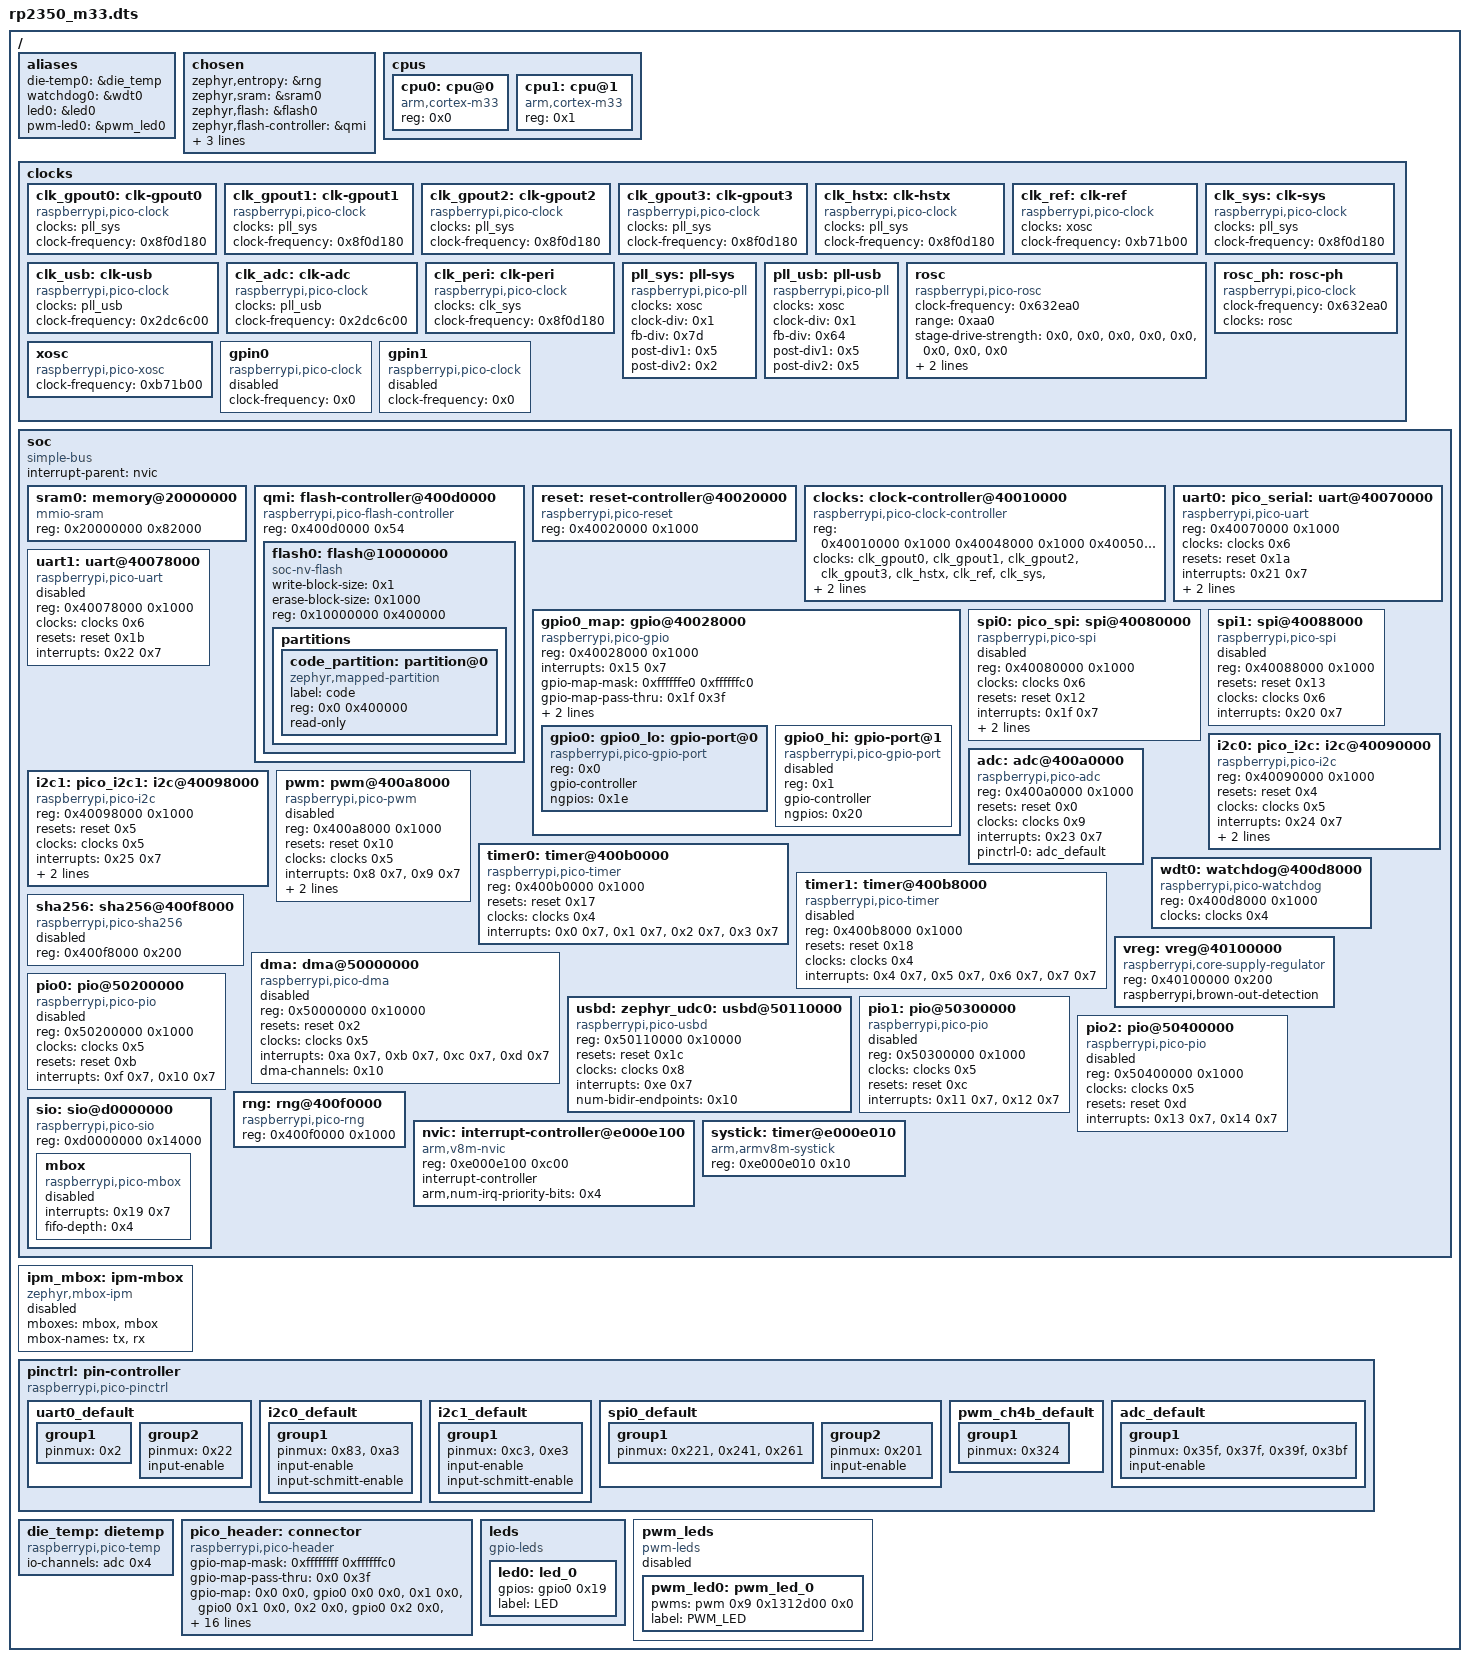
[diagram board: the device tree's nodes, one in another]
/dts-v1/;

/* node '/' defined in zephyr/dts/vendor/raspberrypi/rpi_pico/rp2350.dtsi:19 */
/ {
	#address-cells = < 0x1 >; /* in zephyr/dts/common/skeleton.dtsi:10 */
	#size-cells = < 0x1 >;    /* in zephyr/dts/common/skeleton.dtsi:11 */

	/* node '/aliases' defined in zephyr/dts/vendor/raspberrypi/rpi_pico/rp2350.dtsi:20 */
	aliases {
		die-temp0 = &die_temp; /* in zephyr/dts/vendor/raspberrypi/rpi_pico/rp2350.dtsi:21 */
		watchdog0 = &wdt0;     /* in zephyr/boards/raspberrypi/rpi_pico2/rpi_pico2_cpu0_common.dtsi:26 */
		led0 = &led0;          /* in zephyr/boards/raspberrypi/common/rpi_pico-led.dtsi:29 */
		pwm-led0 = &pwm_led0;  /* in zephyr/boards/raspberrypi/common/rpi_pico-led.dtsi:30 */
	};

	/* node '/chosen' defined in zephyr/dts/vendor/raspberrypi/rpi_pico/rp2350.dtsi:24 */
	chosen {
		zephyr,entropy = &rng;                   /* in zephyr/dts/vendor/raspberrypi/rpi_pico/rp2350.dtsi:25 */
		zephyr,sram = &sram0;                    /* in zephyr/boards/raspberrypi/rpi_pico2/rpi_pico2_cpu0_common.dtsi:17 */
		zephyr,flash = &flash0;                  /* in zephyr/boards/raspberrypi/rpi_pico2/rpi_pico2_cpu0_common.dtsi:18 */
		zephyr,flash-controller = &qmi;          /* in zephyr/boards/raspberrypi/rpi_pico2/rpi_pico2_cpu0_common.dtsi:19 */
		zephyr,console = &uart0;                 /* in zephyr/boards/raspberrypi/rpi_pico2/rpi_pico2_cpu0_common.dtsi:20 */
		zephyr,shell-uart = &uart0;              /* in zephyr/boards/raspberrypi/rpi_pico2/rpi_pico2_cpu0_common.dtsi:21 */
		zephyr,code-partition = &code_partition; /* in zephyr/boards/raspberrypi/rpi_pico2/rpi_pico2_cpu0_common.dtsi:22 */
	};

	/* node '/cpus' defined in zephyr/dts/vendor/raspberrypi/rpi_pico/rp2350.dtsi:28 */
	cpus {
		#address-cells = < 0x1 >; /* in zephyr/dts/vendor/raspberrypi/rpi_pico/rp2350.dtsi:29 */
		#size-cells = < 0x0 >;    /* in zephyr/dts/vendor/raspberrypi/rpi_pico/rp2350.dtsi:30 */

		/* node '/cpus/cpu@0' defined in zephyr/dts/vendor/raspberrypi/rpi_pico/rp2350.dtsi:37 */
		cpu0: cpu@0 {
			reg = < 0x0 >;                 /* in zephyr/dts/vendor/raspberrypi/rpi_pico/rp2350.dtsi:38 */
			compatible = "arm,cortex-m33"; /* in zephyr/dts/arm/raspberrypi/rpi_pico/m33.dtsi:13 */
		};

		/* node '/cpus/cpu@1' defined in zephyr/dts/vendor/raspberrypi/rpi_pico/rp2350.dtsi:41 */
		cpu1: cpu@1 {
			reg = < 0x1 >;                 /* in zephyr/dts/vendor/raspberrypi/rpi_pico/rp2350.dtsi:42 */
			compatible = "arm,cortex-m33"; /* in zephyr/dts/arm/raspberrypi/rpi_pico/m33.dtsi:17 */
		};
	};

	/* node '/clocks' defined in zephyr/dts/vendor/raspberrypi/rpi_pico/rp2350.dtsi:46 */
	clocks {

		/* node '/clocks/clk-gpout0' defined in zephyr/dts/vendor/raspberrypi/rpi_pico/rp2350.dtsi:47 */
		clk_gpout0: clk-gpout0 {
			compatible = "raspberrypi,pico-clock"; /* in zephyr/dts/vendor/raspberrypi/rpi_pico/rp2350.dtsi:48 */
			clocks = < &pll_sys >;                 /* in zephyr/dts/vendor/raspberrypi/rpi_pico/rp2350.dtsi:49 */
			clock-names = "pll_sys";               /* in zephyr/dts/vendor/raspberrypi/rpi_pico/rp2350.dtsi:50 */
			clock-frequency = < 0x8f0d180 >;       /* in zephyr/dts/vendor/raspberrypi/rpi_pico/rp2350.dtsi:51 */
			#clock-cells = < 0x0 >;                /* in zephyr/dts/vendor/raspberrypi/rpi_pico/rp2350.dtsi:52 */
			#address-cells = < 0x0 >;              /* in zephyr/dts/vendor/raspberrypi/rpi_pico/rp2350.dtsi:53 */
			phandle = < 0x7 >;                     /* in zephyr/dts/vendor/raspberrypi/rpi_pico/rp2350.dtsi:230 */
		};

		/* node '/clocks/clk-gpout1' defined in zephyr/dts/vendor/raspberrypi/rpi_pico/rp2350.dtsi:56 */
		clk_gpout1: clk-gpout1 {
			compatible = "raspberrypi,pico-clock"; /* in zephyr/dts/vendor/raspberrypi/rpi_pico/rp2350.dtsi:57 */
			clocks = < &pll_sys >;                 /* in zephyr/dts/vendor/raspberrypi/rpi_pico/rp2350.dtsi:58 */
			clock-names = "pll_sys";               /* in zephyr/dts/vendor/raspberrypi/rpi_pico/rp2350.dtsi:59 */
			clock-frequency = < 0x8f0d180 >;       /* in zephyr/dts/vendor/raspberrypi/rpi_pico/rp2350.dtsi:60 */
			#clock-cells = < 0x0 >;                /* in zephyr/dts/vendor/raspberrypi/rpi_pico/rp2350.dtsi:61 */
			phandle = < 0x8 >;                     /* in zephyr/dts/vendor/raspberrypi/rpi_pico/rp2350.dtsi:230 */
		};

		/* node '/clocks/clk-gpout2' defined in zephyr/dts/vendor/raspberrypi/rpi_pico/rp2350.dtsi:64 */
		clk_gpout2: clk-gpout2 {
			compatible = "raspberrypi,pico-clock"; /* in zephyr/dts/vendor/raspberrypi/rpi_pico/rp2350.dtsi:65 */
			clocks = < &pll_sys >;                 /* in zephyr/dts/vendor/raspberrypi/rpi_pico/rp2350.dtsi:66 */
			clock-names = "pll_sys";               /* in zephyr/dts/vendor/raspberrypi/rpi_pico/rp2350.dtsi:67 */
			clock-frequency = < 0x8f0d180 >;       /* in zephyr/dts/vendor/raspberrypi/rpi_pico/rp2350.dtsi:68 */
			#clock-cells = < 0x0 >;                /* in zephyr/dts/vendor/raspberrypi/rpi_pico/rp2350.dtsi:69 */
			phandle = < 0x9 >;                     /* in zephyr/dts/vendor/raspberrypi/rpi_pico/rp2350.dtsi:230 */
		};

		/* node '/clocks/clk-gpout3' defined in zephyr/dts/vendor/raspberrypi/rpi_pico/rp2350.dtsi:72 */
		clk_gpout3: clk-gpout3 {
			compatible = "raspberrypi,pico-clock"; /* in zephyr/dts/vendor/raspberrypi/rpi_pico/rp2350.dtsi:73 */
			clocks = < &pll_sys >;                 /* in zephyr/dts/vendor/raspberrypi/rpi_pico/rp2350.dtsi:74 */
			clock-names = "pll_sys";               /* in zephyr/dts/vendor/raspberrypi/rpi_pico/rp2350.dtsi:75 */
			clock-frequency = < 0x8f0d180 >;       /* in zephyr/dts/vendor/raspberrypi/rpi_pico/rp2350.dtsi:76 */
			#clock-cells = < 0x0 >;                /* in zephyr/dts/vendor/raspberrypi/rpi_pico/rp2350.dtsi:77 */
			phandle = < 0xa >;                     /* in zephyr/dts/vendor/raspberrypi/rpi_pico/rp2350.dtsi:230 */
		};

		/* node '/clocks/clk-hstx' defined in zephyr/dts/vendor/raspberrypi/rpi_pico/rp2350.dtsi:80 */
		clk_hstx: clk-hstx {
			compatible = "raspberrypi,pico-clock"; /* in zephyr/dts/vendor/raspberrypi/rpi_pico/rp2350.dtsi:81 */
			clocks = < &pll_sys >;                 /* in zephyr/dts/vendor/raspberrypi/rpi_pico/rp2350.dtsi:82 */
			clock-names = "pll_sys";               /* in zephyr/dts/vendor/raspberrypi/rpi_pico/rp2350.dtsi:83 */
			clock-frequency = < 0x8f0d180 >;       /* in zephyr/dts/vendor/raspberrypi/rpi_pico/rp2350.dtsi:84 */
			#clock-cells = < 0x0 >;                /* in zephyr/dts/vendor/raspberrypi/rpi_pico/rp2350.dtsi:85 */
			phandle = < 0xb >;                     /* in zephyr/dts/vendor/raspberrypi/rpi_pico/rp2350.dtsi:230 */
		};

		/* node '/clocks/clk-ref' defined in zephyr/dts/vendor/raspberrypi/rpi_pico/rp2350.dtsi:88 */
		clk_ref: clk-ref {
			compatible = "raspberrypi,pico-clock"; /* in zephyr/dts/vendor/raspberrypi/rpi_pico/rp2350.dtsi:89 */
			clocks = < &xosc >;                    /* in zephyr/dts/vendor/raspberrypi/rpi_pico/rp2350.dtsi:90 */
			clock-names = "xosc";                  /* in zephyr/dts/vendor/raspberrypi/rpi_pico/rp2350.dtsi:91 */
			clock-frequency = < 0xb71b00 >;        /* in zephyr/dts/vendor/raspberrypi/rpi_pico/rp2350.dtsi:92 */
			#clock-cells = < 0x0 >;                /* in zephyr/dts/vendor/raspberrypi/rpi_pico/rp2350.dtsi:93 */
			phandle = < 0xc >;                     /* in zephyr/dts/vendor/raspberrypi/rpi_pico/rp2350.dtsi:230 */
		};

		/* node '/clocks/clk-sys' defined in zephyr/dts/vendor/raspberrypi/rpi_pico/rp2350.dtsi:96 */
		clk_sys: clk-sys {
			compatible = "raspberrypi,pico-clock"; /* in zephyr/dts/vendor/raspberrypi/rpi_pico/rp2350.dtsi:97 */
			clocks = < &pll_sys >;                 /* in zephyr/dts/vendor/raspberrypi/rpi_pico/rp2350.dtsi:98 */
			clock-names = "pll_sys";               /* in zephyr/dts/vendor/raspberrypi/rpi_pico/rp2350.dtsi:99 */
			clock-frequency = < 0x8f0d180 >;       /* in zephyr/dts/vendor/raspberrypi/rpi_pico/rp2350.dtsi:100 */
			#clock-cells = < 0x0 >;                /* in zephyr/dts/vendor/raspberrypi/rpi_pico/rp2350.dtsi:101 */
			phandle = < 0x4 >;                     /* in zephyr/dts/vendor/raspberrypi/rpi_pico/rp2350.dtsi:122 */
		};

		/* node '/clocks/clk-usb' defined in zephyr/dts/vendor/raspberrypi/rpi_pico/rp2350.dtsi:104 */
		clk_usb: clk-usb {
			compatible = "raspberrypi,pico-clock"; /* in zephyr/dts/vendor/raspberrypi/rpi_pico/rp2350.dtsi:105 */
			clocks = < &pll_usb >;                 /* in zephyr/dts/vendor/raspberrypi/rpi_pico/rp2350.dtsi:106 */
			clock-names = "pll_usb";               /* in zephyr/dts/vendor/raspberrypi/rpi_pico/rp2350.dtsi:107 */
			clock-frequency = < 0x2dc6c00 >;       /* in zephyr/dts/vendor/raspberrypi/rpi_pico/rp2350.dtsi:108 */
			#clock-cells = < 0x0 >;                /* in zephyr/dts/vendor/raspberrypi/rpi_pico/rp2350.dtsi:109 */
			phandle = < 0xe >;                     /* in zephyr/dts/vendor/raspberrypi/rpi_pico/rp2350.dtsi:230 */
		};

		/* node '/clocks/clk-adc' defined in zephyr/dts/vendor/raspberrypi/rpi_pico/rp2350.dtsi:112 */
		clk_adc: clk-adc {
			compatible = "raspberrypi,pico-clock"; /* in zephyr/dts/vendor/raspberrypi/rpi_pico/rp2350.dtsi:113 */
			clocks = < &pll_usb >;                 /* in zephyr/dts/vendor/raspberrypi/rpi_pico/rp2350.dtsi:114 */
			clock-names = "pll_usb";               /* in zephyr/dts/vendor/raspberrypi/rpi_pico/rp2350.dtsi:115 */
			clock-frequency = < 0x2dc6c00 >;       /* in zephyr/dts/vendor/raspberrypi/rpi_pico/rp2350.dtsi:116 */
			#clock-cells = < 0x0 >;                /* in zephyr/dts/vendor/raspberrypi/rpi_pico/rp2350.dtsi:117 */
			phandle = < 0xf >;                     /* in zephyr/dts/vendor/raspberrypi/rpi_pico/rp2350.dtsi:230 */
		};

		/* node '/clocks/clk-peri' defined in zephyr/dts/vendor/raspberrypi/rpi_pico/rp2350.dtsi:120 */
		clk_peri: clk-peri {
			compatible = "raspberrypi,pico-clock"; /* in zephyr/dts/vendor/raspberrypi/rpi_pico/rp2350.dtsi:121 */
			clocks = < &clk_sys >;                 /* in zephyr/dts/vendor/raspberrypi/rpi_pico/rp2350.dtsi:122 */
			clock-names = "clk_sys";               /* in zephyr/dts/vendor/raspberrypi/rpi_pico/rp2350.dtsi:123 */
			clock-frequency = < 0x8f0d180 >;       /* in zephyr/dts/vendor/raspberrypi/rpi_pico/rp2350.dtsi:124 */
			#clock-cells = < 0x0 >;                /* in zephyr/dts/vendor/raspberrypi/rpi_pico/rp2350.dtsi:125 */
			phandle = < 0xd >;                     /* in zephyr/dts/vendor/raspberrypi/rpi_pico/rp2350.dtsi:230 */
		};

		/* node '/clocks/pll-sys' defined in zephyr/dts/vendor/raspberrypi/rpi_pico/rp2350.dtsi:128 */
		pll_sys: pll-sys {
			compatible = "raspberrypi,pico-pll"; /* in zephyr/dts/vendor/raspberrypi/rpi_pico/rp2350.dtsi:129 */
			clocks = < &xosc >;                  /* in zephyr/dts/vendor/raspberrypi/rpi_pico/rp2350.dtsi:130 */
			clock-names = "xosc";                /* in zephyr/dts/vendor/raspberrypi/rpi_pico/rp2350.dtsi:131 */
			clock-div = < 0x1 >;                 /* in zephyr/dts/vendor/raspberrypi/rpi_pico/rp2350.dtsi:132 */
			fb-div = < 0x7d >;                   /* in zephyr/dts/vendor/raspberrypi/rpi_pico/rp2350.dtsi:133 */
			post-div1 = < 0x5 >;                 /* in zephyr/dts/vendor/raspberrypi/rpi_pico/rp2350.dtsi:134 */
			post-div2 = < 0x2 >;                 /* in zephyr/dts/vendor/raspberrypi/rpi_pico/rp2350.dtsi:135 */
			#clock-cells = < 0x0 >;              /* in zephyr/dts/vendor/raspberrypi/rpi_pico/rp2350.dtsi:136 */
			phandle = < 0x1 >;                   /* in zephyr/dts/vendor/raspberrypi/rpi_pico/rp2350.dtsi:49 */
		};

		/* node '/clocks/pll-usb' defined in zephyr/dts/vendor/raspberrypi/rpi_pico/rp2350.dtsi:139 */
		pll_usb: pll-usb {
			compatible = "raspberrypi,pico-pll"; /* in zephyr/dts/vendor/raspberrypi/rpi_pico/rp2350.dtsi:140 */
			clocks = < &xosc >;                  /* in zephyr/dts/vendor/raspberrypi/rpi_pico/rp2350.dtsi:141 */
			clock-names = "xosc";                /* in zephyr/dts/vendor/raspberrypi/rpi_pico/rp2350.dtsi:142 */
			clock-div = < 0x1 >;                 /* in zephyr/dts/vendor/raspberrypi/rpi_pico/rp2350.dtsi:143 */
			fb-div = < 0x64 >;                   /* in zephyr/dts/vendor/raspberrypi/rpi_pico/rp2350.dtsi:144 */
			post-div1 = < 0x5 >;                 /* in zephyr/dts/vendor/raspberrypi/rpi_pico/rp2350.dtsi:145 */
			post-div2 = < 0x5 >;                 /* in zephyr/dts/vendor/raspberrypi/rpi_pico/rp2350.dtsi:146 */
			#clock-cells = < 0x0 >;              /* in zephyr/dts/vendor/raspberrypi/rpi_pico/rp2350.dtsi:147 */
			phandle = < 0x3 >;                   /* in zephyr/dts/vendor/raspberrypi/rpi_pico/rp2350.dtsi:106 */
		};

		/* node '/clocks/rosc' defined in zephyr/dts/vendor/raspberrypi/rpi_pico/rp2350.dtsi:150 */
		rosc: rosc {
			compatible = "raspberrypi,pico-rosc"; /* in zephyr/dts/vendor/raspberrypi/rpi_pico/rp2350.dtsi:151 */
			clock-frequency = < 0x632ea0 >;       /* in zephyr/dts/vendor/raspberrypi/rpi_pico/rp2350.dtsi:152 */
			range = < 0xaa0 >;                    /* in zephyr/dts/vendor/raspberrypi/rpi_pico/rp2350.dtsi:153 */
			stage-drive-strength = < 0x0 >,
			                       < 0x0 >,
			                       < 0x0 >,
			                       < 0x0 >,
			                       < 0x0 >,
			                       < 0x0 >,
			                       < 0x0 >,
			                       < 0x0 >;       /* in zephyr/dts/vendor/raspberrypi/rpi_pico/rp2350.dtsi:154 */
			clock-div = < 0x10 >;                 /* in zephyr/dts/vendor/raspberrypi/rpi_pico/rp2350.dtsi:155 */
			phase = < 0x0 >;                      /* in zephyr/dts/vendor/raspberrypi/rpi_pico/rp2350.dtsi:156 */
			#clock-cells = < 0x0 >;               /* in zephyr/dts/vendor/raspberrypi/rpi_pico/rp2350.dtsi:157 */
			phandle = < 0x5 >;                    /* in zephyr/dts/vendor/raspberrypi/rpi_pico/rp2350.dtsi:163 */
		};

		/* node '/clocks/rosc-ph' defined in zephyr/dts/vendor/raspberrypi/rpi_pico/rp2350.dtsi:160 */
		rosc_ph: rosc-ph {
			compatible = "raspberrypi,pico-clock"; /* in zephyr/dts/vendor/raspberrypi/rpi_pico/rp2350.dtsi:161 */
			clock-frequency = < 0x632ea0 >;        /* in zephyr/dts/vendor/raspberrypi/rpi_pico/rp2350.dtsi:162 */
			clocks = < &rosc >;                    /* in zephyr/dts/vendor/raspberrypi/rpi_pico/rp2350.dtsi:163 */
			clock-names = "rosc";                  /* in zephyr/dts/vendor/raspberrypi/rpi_pico/rp2350.dtsi:164 */
			#clock-cells = < 0x0 >;                /* in zephyr/dts/vendor/raspberrypi/rpi_pico/rp2350.dtsi:165 */
			phandle = < 0x10 >;                    /* in zephyr/dts/vendor/raspberrypi/rpi_pico/rp2350.dtsi:230 */
		};

		/* node '/clocks/xosc' defined in zephyr/dts/vendor/raspberrypi/rpi_pico/rp2350.dtsi:168 */
		xosc: xosc {
			compatible = "raspberrypi,pico-xosc"; /* in zephyr/dts/vendor/raspberrypi/rpi_pico/rp2350.dtsi:169 */
			clock-frequency = < 0xb71b00 >;       /* in zephyr/dts/vendor/raspberrypi/rpi_pico/rp2350.dtsi:170 */
			#clock-cells = < 0x0 >;               /* in zephyr/dts/vendor/raspberrypi/rpi_pico/rp2350.dtsi:171 */
			phandle = < 0x2 >;                    /* in zephyr/dts/vendor/raspberrypi/rpi_pico/rp2350.dtsi:90 */
		};

		/* node '/clocks/gpin0' defined in zephyr/dts/vendor/raspberrypi/rpi_pico/rp2350.dtsi:174 */
		gpin0: gpin0 {
			compatible = "raspberrypi,pico-clock"; /* in zephyr/dts/vendor/raspberrypi/rpi_pico/rp2350.dtsi:175 */
			status = "disabled";                   /* in zephyr/dts/vendor/raspberrypi/rpi_pico/rp2350.dtsi:176 */
			clock-frequency = < 0x0 >;             /* in zephyr/dts/vendor/raspberrypi/rpi_pico/rp2350.dtsi:177 */
			#clock-cells = < 0x0 >;                /* in zephyr/dts/vendor/raspberrypi/rpi_pico/rp2350.dtsi:178 */
			phandle = < 0x11 >;                    /* in zephyr/dts/vendor/raspberrypi/rpi_pico/rp2350.dtsi:230 */
		};

		/* node '/clocks/gpin1' defined in zephyr/dts/vendor/raspberrypi/rpi_pico/rp2350.dtsi:181 */
		gpin1: gpin1 {
			compatible = "raspberrypi,pico-clock"; /* in zephyr/dts/vendor/raspberrypi/rpi_pico/rp2350.dtsi:182 */
			status = "disabled";                   /* in zephyr/dts/vendor/raspberrypi/rpi_pico/rp2350.dtsi:183 */
			clock-frequency = < 0x0 >;             /* in zephyr/dts/vendor/raspberrypi/rpi_pico/rp2350.dtsi:184 */
			#clock-cells = < 0x0 >;                /* in zephyr/dts/vendor/raspberrypi/rpi_pico/rp2350.dtsi:185 */
			phandle = < 0x12 >;                    /* in zephyr/dts/vendor/raspberrypi/rpi_pico/rp2350.dtsi:230 */
		};
	};

	/* node '/soc' defined in zephyr/dts/vendor/raspberrypi/rpi_pico/rp2350.dtsi:189 */
	soc {
		#address-cells = < 0x1 >;     /* in zephyr/dts/arm/armv8-m.dtsi:7 */
		#size-cells = < 0x1 >;        /* in zephyr/dts/arm/armv8-m.dtsi:8 */
		compatible = "simple-bus";    /* in zephyr/dts/arm/armv8-m.dtsi:9 */
		interrupt-parent = < &nvic >; /* in zephyr/dts/arm/armv8-m.dtsi:10 */
		ranges;                       /* in zephyr/dts/arm/armv8-m.dtsi:11 */

		/* node '/soc/memory@20000000' defined in zephyr/dts/vendor/raspberrypi/rpi_pico/rp2350.dtsi:192 */
		sram0: memory@20000000 {
			compatible = "mmio-sram";     /* in zephyr/dts/vendor/raspberrypi/rpi_pico/rp2350.dtsi:193 */
			reg = < 0x20000000 0x82000 >; /* in zephyr/dts/vendor/raspberrypi/rpi_pico/rp2350.dtsi:194 */
		};

		/* node '/soc/flash-controller@400d0000' defined in zephyr/dts/vendor/raspberrypi/rpi_pico/rp2350.dtsi:197 */
		qmi: flash-controller@400d0000 {
			compatible = "raspberrypi,pico-flash-controller"; /* in zephyr/dts/vendor/raspberrypi/rpi_pico/rp2350.dtsi:198 */
			reg = < 0x400d0000 0x54 >;                        /* in zephyr/dts/vendor/raspberrypi/rpi_pico/rp2350.dtsi:199 */
			#address-cells = < 0x1 >;                         /* in zephyr/dts/vendor/raspberrypi/rpi_pico/rp2350.dtsi:201 */
			#size-cells = < 0x1 >;                            /* in zephyr/dts/vendor/raspberrypi/rpi_pico/rp2350.dtsi:202 */
			ranges;                                           /* in zephyr/dts/vendor/raspberrypi/rpi_pico/rp2350.dtsi:203 */

			/* node '/soc/flash-controller@400d0000/flash@10000000' defined in zephyr/dts/vendor/raspberrypi/rpi_pico/rp2350.dtsi:205 */
			flash0: flash@10000000 {
				compatible = "soc-nv-flash";          /* in zephyr/dts/vendor/raspberrypi/rpi_pico/rp2350.dtsi:206 */
				write-block-size = < 0x1 >;           /* in zephyr/dts/vendor/raspberrypi/rpi_pico/rp2350.dtsi:207 */
				erase-block-size = < 0x1000 >;        /* in zephyr/dts/vendor/raspberrypi/rpi_pico/rp2350.dtsi:208 */
				#address-cells = < 0x1 >;             /* in zephyr/dts/vendor/raspberrypi/rpi_pico/rp2350.dtsi:209 */
				#size-cells = < 0x1 >;                /* in zephyr/dts/vendor/raspberrypi/rpi_pico/rp2350.dtsi:210 */
				reg = < 0x10000000 0x400000 >;        /* in zephyr/boards/raspberrypi/rpi_pico2/rpi_pico2_common.dtsi:47 */
				ranges = < 0x0 0x10000000 0x400000 >; /* in zephyr/boards/raspberrypi/rpi_pico2/rpi_pico2_common.dtsi:48 */

				/* node '/soc/flash-controller@400d0000/flash@10000000/partitions' defined in zephyr/dts/vendor/raspberrypi/partitions_0x0_default_4M.dtsi:8 */
				partitions {
					ranges;                   /* in zephyr/dts/vendor/raspberrypi/partitions_0x0_default_4M.dtsi:9 */
					#address-cells = < 0x1 >; /* in zephyr/dts/vendor/raspberrypi/partitions_0x0_default_4M.dtsi:10 */
					#size-cells = < 0x1 >;    /* in zephyr/dts/vendor/raspberrypi/partitions_0x0_default_4M.dtsi:11 */

					/* node '/soc/flash-controller@400d0000/flash@10000000/partitions/partition@0' defined in zephyr/dts/vendor/raspberrypi/partitions_0x0_default_4M.dtsi:13 */
					code_partition: partition@0 {
						compatible = "zephyr,mapped-partition"; /* in zephyr/dts/vendor/raspberrypi/partitions_0x0_default_4M.dtsi:14 */
						label = "code";                         /* in zephyr/dts/vendor/raspberrypi/partitions_0x0_default_4M.dtsi:15 */
						reg = < 0x0 0x400000 >;                 /* in zephyr/dts/vendor/raspberrypi/partitions_0x0_default_4M.dtsi:16 */
						read-only;                              /* in zephyr/dts/vendor/raspberrypi/partitions_0x0_default_4M.dtsi:17 */
					};
				};
			};
		};

		/* node '/soc/reset-controller@40020000' defined in zephyr/dts/vendor/raspberrypi/rpi_pico/rp2350.dtsi:214 */
		reset: reset-controller@40020000 {
			compatible = "raspberrypi,pico-reset"; /* in zephyr/dts/vendor/raspberrypi/rpi_pico/rp2350.dtsi:215 */
			reg = < 0x40020000 0x1000 >;           /* in zephyr/dts/vendor/raspberrypi/rpi_pico/rp2350.dtsi:216 */
			#reset-cells = < 0x1 >;                /* in zephyr/dts/vendor/raspberrypi/rpi_pico/rp2350.dtsi:217 */
			phandle = < 0x16 >;                    /* in zephyr/dts/vendor/raspberrypi/rpi_pico/rp2350.dtsi:278 */
		};

		/* node '/soc/clock-controller@40010000' defined in zephyr/dts/vendor/raspberrypi/rpi_pico/rp2350.dtsi:220 */
		clocks: clock-controller@40010000 {
			compatible = "raspberrypi,pico-clock-controller";                                          /* in zephyr/dts/vendor/raspberrypi/rpi_pico/rp2350.dtsi:221 */
			reg = < 0x40010000 0x1000 0x40048000 0x1000 0x40050000 0x1000 0x40058000 0x1000 0x400e8000
			        0x1000 >;                                                                          /* in zephyr/dts/vendor/raspberrypi/rpi_pico/rp2350.dtsi:222 */
			reg-names = "clocks",
			            "xosc",
			            "pll_sys",
			            "pll_usb",
			            "rosc";                                                                        /* in zephyr/dts/vendor/raspberrypi/rpi_pico/rp2350.dtsi:227 */
			#clock-cells = < 0x1 >;                                                                    /* in zephyr/dts/vendor/raspberrypi/rpi_pico/rp2350.dtsi:228 */
			status = "okay";                                                                           /* in zephyr/dts/vendor/raspberrypi/rpi_pico/rp2350.dtsi:229 */
			clocks = < &clk_gpout0 >,
			         < &clk_gpout1 >,
			         < &clk_gpout2 >,
			         < &clk_gpout3 >,
			         < &clk_hstx >,
			         < &clk_ref >,
			         < &clk_sys >,
			         < &clk_peri >,
			         < &clk_usb >,
			         < &clk_adc >,
			         < &pll_sys >,
			         < &pll_usb >,
			         < &xosc >,
			         < &rosc >,
			         < &rosc_ph >,
			         < &gpin0 >,
			         < &gpin1 >;                                                                       /* in zephyr/dts/vendor/raspberrypi/rpi_pico/rp2350.dtsi:230 */
			clock-names = "clk_gpout0",
			              "clk_gpout1",
			              "clk_gpout2",
			              "clk_gpout3",
			              "clk_hstx",
			              "clk_ref",
			              "clk_sys",
			              "clk_peri",
			              "clk_usb",
			              "clk_adc",
			              "pll_sys",
			              "pll_usb",
			              "xosc",
			              "rosc",
			              "rosc_ph",
			              "gpin0",
			              "gpin1";                                                                     /* in zephyr/dts/vendor/raspberrypi/rpi_pico/rp2350.dtsi:235 */
			phandle = < 0x15 >;                                                                        /* in zephyr/dts/vendor/raspberrypi/rpi_pico/rp2350.dtsi:277 */
		};

		/* node '/soc/gpio@40028000' defined in zephyr/dts/vendor/raspberrypi/rpi_pico/rp2350.dtsi:242 */
		gpio0_map: gpio@40028000 {
			compatible = "raspberrypi,pico-gpio";                             /* in zephyr/dts/vendor/raspberrypi/rpi_pico/rp2350.dtsi:243 */
			reg = < 0x40028000 0x1000 >;                                      /* in zephyr/dts/vendor/raspberrypi/rpi_pico/rp2350.dtsi:244 */
			interrupts = < 0x15 0x7 >;                                        /* in zephyr/dts/vendor/raspberrypi/rpi_pico/rp2350.dtsi:245 */
			gpio-map-mask = < 0xffffffe0 0xffffffc0 >;                        /* in zephyr/dts/vendor/raspberrypi/rpi_pico/rp2350.dtsi:247 */
			gpio-map-pass-thru = < 0x1f 0x3f >;                               /* in zephyr/dts/vendor/raspberrypi/rpi_pico/rp2350.dtsi:248 */
			gpio-map = < 0x0 0x0 &gpio0 0x0 0x0 0x20 0x0 &gpio0_hi 0x0 0x0 >; /* in zephyr/dts/vendor/raspberrypi/rpi_pico/rp2350.dtsi:249 */
			#gpio-cells = < 0x2 >;                                            /* in zephyr/dts/vendor/raspberrypi/rpi_pico/rp2350.dtsi:251 */
			#address-cells = < 0x1 >;                                         /* in zephyr/dts/vendor/raspberrypi/rpi_pico/rp2350.dtsi:252 */
			#size-cells = < 0x0 >;                                            /* in zephyr/dts/vendor/raspberrypi/rpi_pico/rp2350.dtsi:253 */

			/* node '/soc/gpio@40028000/gpio-port@0' defined in zephyr/dts/vendor/raspberrypi/rpi_pico/rp2350.dtsi:255 */
			gpio0: gpio0_lo: gpio-port@0 {
				compatible = "raspberrypi,pico-gpio-port"; /* in zephyr/dts/vendor/raspberrypi/rpi_pico/rp2350.dtsi:256 */
				reg = < 0x0 >;                             /* in zephyr/dts/vendor/raspberrypi/rpi_pico/rp2350.dtsi:257 */
				gpio-controller;                           /* in zephyr/dts/vendor/raspberrypi/rpi_pico/rp2350.dtsi:259 */
				#gpio-cells = < 0x2 >;                     /* in zephyr/dts/vendor/raspberrypi/rpi_pico/rp2350.dtsi:260 */
				ngpios = < 0x1e >;                         /* in zephyr/dts/vendor/raspberrypi/rpi_pico/rp2350a.dtsi:4 */
				status = "okay";                           /* in zephyr/boards/raspberrypi/rpi_pico2/rpi_pico2_common.dtsi:52 */
				phandle = < 0x13 >;                        /* in zephyr/dts/vendor/raspberrypi/rpi_pico/rp2350.dtsi:249 */
			};

			/* node '/soc/gpio@40028000/gpio-port@1' defined in zephyr/dts/vendor/raspberrypi/rpi_pico/rp2350.dtsi:264 */
			gpio0_hi: gpio-port@1 {
				compatible = "raspberrypi,pico-gpio-port"; /* in zephyr/dts/vendor/raspberrypi/rpi_pico/rp2350.dtsi:265 */
				reg = < 0x1 >;                             /* in zephyr/dts/vendor/raspberrypi/rpi_pico/rp2350.dtsi:266 */
				status = "disabled";                       /* in zephyr/dts/vendor/raspberrypi/rpi_pico/rp2350.dtsi:267 */
				gpio-controller;                           /* in zephyr/dts/vendor/raspberrypi/rpi_pico/rp2350.dtsi:268 */
				#gpio-cells = < 0x2 >;                     /* in zephyr/dts/vendor/raspberrypi/rpi_pico/rp2350.dtsi:269 */
				ngpios = < 0x20 >;                         /* in zephyr/dts/vendor/raspberrypi/rpi_pico/rp2350.dtsi:270 */
				phandle = < 0x14 >;                        /* in zephyr/dts/vendor/raspberrypi/rpi_pico/rp2350.dtsi:249 */
			};
		};

		/* node '/soc/uart@40070000' defined in zephyr/dts/vendor/raspberrypi/rpi_pico/rp2350.dtsi:274 */
		uart0: pico_serial: pico_serial0: uart@40070000 {
			compatible = "raspberrypi,pico-uart",
			             "arm,pl011";             /* in zephyr/dts/vendor/raspberrypi/rpi_pico/rp2350.dtsi:275 */
			reg = < 0x40070000 0x1000 >;          /* in zephyr/dts/vendor/raspberrypi/rpi_pico/rp2350.dtsi:276 */
			clocks = < &clocks 0x6 >;             /* in zephyr/dts/vendor/raspberrypi/rpi_pico/rp2350.dtsi:277 */
			resets = < &reset 0x1a >;             /* in zephyr/dts/vendor/raspberrypi/rpi_pico/rp2350.dtsi:278 */
			interrupts = < 0x21 0x7 >;            /* in zephyr/dts/vendor/raspberrypi/rpi_pico/rp2350.dtsi:279 */
			interrupt-names = "uart0";            /* in zephyr/dts/vendor/raspberrypi/rpi_pico/rp2350.dtsi:280 */
			current-speed = < 0x1c200 >;          /* in zephyr/boards/raspberrypi/rpi_pico2/rpi_pico2_cpu0_common.dtsi:31 */
			status = "okay";                      /* in zephyr/boards/raspberrypi/rpi_pico2/rpi_pico2_cpu0_common.dtsi:32 */
			pinctrl-0 = < &uart0_default >;       /* in zephyr/boards/raspberrypi/rpi_pico2/rpi_pico2_cpu0_common.dtsi:33 */
			pinctrl-names = "default";            /* in zephyr/boards/raspberrypi/rpi_pico2/rpi_pico2_cpu0_common.dtsi:34 */
		};

		/* node '/soc/uart@40078000' defined in zephyr/dts/vendor/raspberrypi/rpi_pico/rp2350.dtsi:284 */
		uart1: uart@40078000 {
			compatible = "raspberrypi,pico-uart",
			             "arm,pl011";             /* in zephyr/dts/vendor/raspberrypi/rpi_pico/rp2350.dtsi:285 */
			reg = < 0x40078000 0x1000 >;          /* in zephyr/dts/vendor/raspberrypi/rpi_pico/rp2350.dtsi:286 */
			clocks = < &clocks 0x6 >;             /* in zephyr/dts/vendor/raspberrypi/rpi_pico/rp2350.dtsi:287 */
			resets = < &reset 0x1b >;             /* in zephyr/dts/vendor/raspberrypi/rpi_pico/rp2350.dtsi:288 */
			interrupts = < 0x22 0x7 >;            /* in zephyr/dts/vendor/raspberrypi/rpi_pico/rp2350.dtsi:289 */
			interrupt-names = "uart1";            /* in zephyr/dts/vendor/raspberrypi/rpi_pico/rp2350.dtsi:290 */
			status = "disabled";                  /* in zephyr/dts/vendor/raspberrypi/rpi_pico/rp2350.dtsi:291 */
		};

		/* node '/soc/spi@40080000' defined in zephyr/dts/vendor/raspberrypi/rpi_pico/rp2350.dtsi:294 */
		spi0: pico_spi: pico_spi0: spi@40080000 {
			compatible = "raspberrypi,pico-spi",
			             "arm,pl022";            /* in zephyr/dts/vendor/raspberrypi/rpi_pico/rp2350.dtsi:295 */
			#address-cells = < 0x1 >;            /* in zephyr/dts/vendor/raspberrypi/rpi_pico/rp2350.dtsi:296 */
			#size-cells = < 0x0 >;               /* in zephyr/dts/vendor/raspberrypi/rpi_pico/rp2350.dtsi:297 */
			reg = < 0x40080000 0x1000 >;         /* in zephyr/dts/vendor/raspberrypi/rpi_pico/rp2350.dtsi:298 */
			clocks = < &clocks 0x6 >;            /* in zephyr/dts/vendor/raspberrypi/rpi_pico/rp2350.dtsi:299 */
			resets = < &reset 0x12 >;            /* in zephyr/dts/vendor/raspberrypi/rpi_pico/rp2350.dtsi:300 */
			interrupts = < 0x1f 0x7 >;           /* in zephyr/dts/vendor/raspberrypi/rpi_pico/rp2350.dtsi:301 */
			interrupt-names = "spi0";            /* in zephyr/dts/vendor/raspberrypi/rpi_pico/rp2350.dtsi:302 */
			status = "disabled";                 /* in zephyr/dts/vendor/raspberrypi/rpi_pico/rp2350.dtsi:303 */
			clock-frequency = < 0x7a1200 >;      /* in zephyr/boards/raspberrypi/rpi_pico2/rpi_pico2_cpu0_common.dtsi:38 */
			pinctrl-0 = < &spi0_default >;       /* in zephyr/boards/raspberrypi/rpi_pico2/rpi_pico2_cpu0_common.dtsi:39 */
			pinctrl-names = "default";           /* in zephyr/boards/raspberrypi/rpi_pico2/rpi_pico2_cpu0_common.dtsi:40 */
		};

		/* node '/soc/spi@40088000' defined in zephyr/dts/vendor/raspberrypi/rpi_pico/rp2350.dtsi:306 */
		spi1: spi@40088000 {
			compatible = "raspberrypi,pico-spi",
			             "arm,pl022";            /* in zephyr/dts/vendor/raspberrypi/rpi_pico/rp2350.dtsi:307 */
			#address-cells = < 0x1 >;            /* in zephyr/dts/vendor/raspberrypi/rpi_pico/rp2350.dtsi:308 */
			#size-cells = < 0x0 >;               /* in zephyr/dts/vendor/raspberrypi/rpi_pico/rp2350.dtsi:309 */
			reg = < 0x40088000 0x1000 >;         /* in zephyr/dts/vendor/raspberrypi/rpi_pico/rp2350.dtsi:310 */
			resets = < &reset 0x13 >;            /* in zephyr/dts/vendor/raspberrypi/rpi_pico/rp2350.dtsi:311 */
			clocks = < &clocks 0x6 >;            /* in zephyr/dts/vendor/raspberrypi/rpi_pico/rp2350.dtsi:312 */
			interrupts = < 0x20 0x7 >;           /* in zephyr/dts/vendor/raspberrypi/rpi_pico/rp2350.dtsi:313 */
			interrupt-names = "spi1";            /* in zephyr/dts/vendor/raspberrypi/rpi_pico/rp2350.dtsi:314 */
			status = "disabled";                 /* in zephyr/dts/vendor/raspberrypi/rpi_pico/rp2350.dtsi:315 */
		};

		/* node '/soc/i2c@40090000' defined in zephyr/dts/vendor/raspberrypi/rpi_pico/rp2350.dtsi:318 */
		i2c0: pico_i2c: pico_i2c0: i2c@40090000 {
			compatible = "raspberrypi,pico-i2c",
			             "snps,designware-i2c";  /* in zephyr/dts/vendor/raspberrypi/rpi_pico/rp2350.dtsi:319 */
			#address-cells = < 0x1 >;            /* in zephyr/dts/vendor/raspberrypi/rpi_pico/rp2350.dtsi:320 */
			#size-cells = < 0x0 >;               /* in zephyr/dts/vendor/raspberrypi/rpi_pico/rp2350.dtsi:321 */
			reg = < 0x40090000 0x1000 >;         /* in zephyr/dts/vendor/raspberrypi/rpi_pico/rp2350.dtsi:322 */
			resets = < &reset 0x4 >;             /* in zephyr/dts/vendor/raspberrypi/rpi_pico/rp2350.dtsi:323 */
			clocks = < &clocks 0x5 >;            /* in zephyr/dts/vendor/raspberrypi/rpi_pico/rp2350.dtsi:324 */
			interrupts = < 0x24 0x7 >;           /* in zephyr/dts/vendor/raspberrypi/rpi_pico/rp2350.dtsi:325 */
			interrupt-names = "i2c0";            /* in zephyr/dts/vendor/raspberrypi/rpi_pico/rp2350.dtsi:326 */
			clock-frequency = < 0x186a0 >;       /* in zephyr/boards/raspberrypi/rpi_pico2/rpi_pico2_cpu0_common.dtsi:44 */
			pinctrl-0 = < &i2c0_default >;       /* in zephyr/boards/raspberrypi/rpi_pico2/rpi_pico2_cpu0_common.dtsi:45 */
			pinctrl-names = "default";           /* in zephyr/boards/raspberrypi/rpi_pico2/rpi_pico2_cpu0_common.dtsi:46 */
			status = "okay";                     /* in zephyr/boards/raspberrypi/rpi_pico2/rpi_pico2_cpu0_common.dtsi:47 */
		};

		/* node '/soc/i2c@40098000' defined in zephyr/dts/vendor/raspberrypi/rpi_pico/rp2350.dtsi:330 */
		i2c1: pico_i2c1: i2c@40098000 {
			compatible = "raspberrypi,pico-i2c",
			             "snps,designware-i2c";  /* in zephyr/dts/vendor/raspberrypi/rpi_pico/rp2350.dtsi:331 */
			#address-cells = < 0x1 >;            /* in zephyr/dts/vendor/raspberrypi/rpi_pico/rp2350.dtsi:332 */
			#size-cells = < 0x0 >;               /* in zephyr/dts/vendor/raspberrypi/rpi_pico/rp2350.dtsi:333 */
			reg = < 0x40098000 0x1000 >;         /* in zephyr/dts/vendor/raspberrypi/rpi_pico/rp2350.dtsi:334 */
			resets = < &reset 0x5 >;             /* in zephyr/dts/vendor/raspberrypi/rpi_pico/rp2350.dtsi:335 */
			clocks = < &clocks 0x5 >;            /* in zephyr/dts/vendor/raspberrypi/rpi_pico/rp2350.dtsi:336 */
			interrupts = < 0x25 0x7 >;           /* in zephyr/dts/vendor/raspberrypi/rpi_pico/rp2350.dtsi:337 */
			interrupt-names = "i2c1";            /* in zephyr/dts/vendor/raspberrypi/rpi_pico/rp2350.dtsi:338 */
			clock-frequency = < 0x186a0 >;       /* in zephyr/boards/raspberrypi/rpi_pico2/rpi_pico2_cpu0_common.dtsi:51 */
			pinctrl-0 = < &i2c1_default >;       /* in zephyr/boards/raspberrypi/rpi_pico2/rpi_pico2_cpu0_common.dtsi:52 */
			pinctrl-names = "default";           /* in zephyr/boards/raspberrypi/rpi_pico2/rpi_pico2_cpu0_common.dtsi:53 */
			status = "okay";                     /* in zephyr/boards/raspberrypi/rpi_pico2/rpi_pico2_cpu0_common.dtsi:54 */
		};

		/* node '/soc/adc@400a0000' defined in zephyr/dts/vendor/raspberrypi/rpi_pico/rp2350.dtsi:342 */
		adc: adc@400a0000 {
			compatible = "raspberrypi,pico-adc"; /* in zephyr/dts/vendor/raspberrypi/rpi_pico/rp2350.dtsi:343 */
			reg = < 0x400a0000 0x1000 >;         /* in zephyr/dts/vendor/raspberrypi/rpi_pico/rp2350.dtsi:344 */
			resets = < &reset 0x0 >;             /* in zephyr/dts/vendor/raspberrypi/rpi_pico/rp2350.dtsi:345 */
			clocks = < &clocks 0x9 >;            /* in zephyr/dts/vendor/raspberrypi/rpi_pico/rp2350.dtsi:346 */
			interrupts = < 0x23 0x7 >;           /* in zephyr/dts/vendor/raspberrypi/rpi_pico/rp2350.dtsi:347 */
			interrupt-names = "adc0";            /* in zephyr/dts/vendor/raspberrypi/rpi_pico/rp2350.dtsi:348 */
			#io-channel-cells = < 0x1 >;         /* in zephyr/dts/vendor/raspberrypi/rpi_pico/rp2350.dtsi:350 */
			pinctrl-0 = < &adc_default >;        /* in zephyr/boards/raspberrypi/rpi_pico2/rpi_pico2_cpu0_common.dtsi:58 */
			pinctrl-names = "default";           /* in zephyr/boards/raspberrypi/rpi_pico2/rpi_pico2_cpu0_common.dtsi:59 */
			status = "okay";                     /* in zephyr/boards/raspberrypi/rpi_pico2/rpi_pico2_cpu0_common.dtsi:60 */
			phandle = < 0x1e >;                  /* in zephyr/dts/vendor/raspberrypi/rpi_pico/rp2350a.dtsi:8 */
		};

		/* node '/soc/pwm@400a8000' defined in zephyr/dts/vendor/raspberrypi/rpi_pico/rp2350.dtsi:353 */
		pwm: pwm@400a8000 {
			compatible = "raspberrypi,pico-pwm"; /* in zephyr/dts/vendor/raspberrypi/rpi_pico/rp2350.dtsi:354 */
			reg = < 0x400a8000 0x1000 >;         /* in zephyr/dts/vendor/raspberrypi/rpi_pico/rp2350.dtsi:355 */
			resets = < &reset 0x10 >;            /* in zephyr/dts/vendor/raspberrypi/rpi_pico/rp2350.dtsi:356 */
			clocks = < &clocks 0x5 >;            /* in zephyr/dts/vendor/raspberrypi/rpi_pico/rp2350.dtsi:357 */
			interrupts = < 0x8 0x7 >,
			             < 0x9 0x7 >;            /* in zephyr/dts/vendor/raspberrypi/rpi_pico/rp2350.dtsi:358 */
			interrupt-names = "PWM_IRQ_WRAP_0",
			                  "PWM_IRQ_WRAP_1";  /* in zephyr/dts/vendor/raspberrypi/rpi_pico/rp2350.dtsi:360 */
			status = "disabled";                 /* in zephyr/dts/vendor/raspberrypi/rpi_pico/rp2350.dtsi:362 */
			#pwm-cells = < 0x3 >;                /* in zephyr/dts/vendor/raspberrypi/rpi_pico/rp2350.dtsi:363 */
			pinctrl-0 = < &pwm_ch4b_default >;   /* in zephyr/boards/raspberrypi/rpi_pico2/rpi_pico2_cpu0_common.dtsi:64 */
			pinctrl-names = "default";           /* in zephyr/boards/raspberrypi/rpi_pico2/rpi_pico2_cpu0_common.dtsi:65 */
			divider-int-0 = < 0xff >;            /* in zephyr/boards/raspberrypi/rpi_pico2/rpi_pico2_cpu0_common.dtsi:66 */
			phandle = < 0x1f >;                  /* in zephyr/boards/raspberrypi/common/rpi_pico-led.dtsi:23 */
		};

		/* node '/soc/timer@400b0000' defined in zephyr/dts/vendor/raspberrypi/rpi_pico/rp2350.dtsi:366 */
		timer0: timer@400b0000 {
			compatible = "raspberrypi,pico-timer"; /* in zephyr/dts/vendor/raspberrypi/rpi_pico/rp2350.dtsi:367 */
			reg = < 0x400b0000 0x1000 >;           /* in zephyr/dts/vendor/raspberrypi/rpi_pico/rp2350.dtsi:368 */
			resets = < &reset 0x17 >;              /* in zephyr/dts/vendor/raspberrypi/rpi_pico/rp2350.dtsi:369 */
			clocks = < &clocks 0x4 >;              /* in zephyr/dts/vendor/raspberrypi/rpi_pico/rp2350.dtsi:370 */
			interrupts = < 0x0 0x7 >,
			             < 0x1 0x7 >,
			             < 0x2 0x7 >,
			             < 0x3 0x7 >;              /* in zephyr/dts/vendor/raspberrypi/rpi_pico/rp2350.dtsi:371 */
			interrupt-names = "TIMER0_IRQ_0",
			                  "TIMER0_IRQ_1",
			                  "TIMER0_IRQ_2",
			                  "TIMER0_IRQ_3";      /* in zephyr/dts/vendor/raspberrypi/rpi_pico/rp2350.dtsi:375 */
			status = "okay";                       /* in zephyr/boards/raspberrypi/rpi_pico2/rpi_pico2_cpu0_common.dtsi:70 */
		};

		/* node '/soc/timer@400b8000' defined in zephyr/dts/vendor/raspberrypi/rpi_pico/rp2350.dtsi:382 */
		timer1: timer@400b8000 {
			compatible = "raspberrypi,pico-timer"; /* in zephyr/dts/vendor/raspberrypi/rpi_pico/rp2350.dtsi:383 */
			reg = < 0x400b8000 0x1000 >;           /* in zephyr/dts/vendor/raspberrypi/rpi_pico/rp2350.dtsi:384 */
			resets = < &reset 0x18 >;              /* in zephyr/dts/vendor/raspberrypi/rpi_pico/rp2350.dtsi:385 */
			clocks = < &clocks 0x4 >;              /* in zephyr/dts/vendor/raspberrypi/rpi_pico/rp2350.dtsi:386 */
			interrupts = < 0x4 0x7 >,
			             < 0x5 0x7 >,
			             < 0x6 0x7 >,
			             < 0x7 0x7 >;              /* in zephyr/dts/vendor/raspberrypi/rpi_pico/rp2350.dtsi:387 */
			interrupt-names = "TIMER1_IRQ_0",
			                  "TIMER1_IRQ_1",
			                  "TIMER1_IRQ_2",
			                  "TIMER1_IRQ_3";      /* in zephyr/dts/vendor/raspberrypi/rpi_pico/rp2350.dtsi:391 */
			status = "disabled";                   /* in zephyr/dts/vendor/raspberrypi/rpi_pico/rp2350.dtsi:395 */
		};

		/* node '/soc/watchdog@400d8000' defined in zephyr/dts/vendor/raspberrypi/rpi_pico/rp2350.dtsi:398 */
		wdt0: watchdog@400d8000 {
			compatible = "raspberrypi,pico-watchdog"; /* in zephyr/dts/vendor/raspberrypi/rpi_pico/rp2350.dtsi:399 */
			reg = < 0x400d8000 0x1000 >;              /* in zephyr/dts/vendor/raspberrypi/rpi_pico/rp2350.dtsi:400 */
			clocks = < &clocks 0x4 >;                 /* in zephyr/dts/vendor/raspberrypi/rpi_pico/rp2350.dtsi:401 */
			status = "okay";                          /* in zephyr/boards/raspberrypi/rpi_pico2/rpi_pico2_cpu0_common.dtsi:74 */
		};

		/* node '/soc/sha256@400f8000' defined in zephyr/dts/vendor/raspberrypi/rpi_pico/rp2350.dtsi:405 */
		sha256: sha256@400f8000 {
			compatible = "raspberrypi,pico-sha256"; /* in zephyr/dts/vendor/raspberrypi/rpi_pico/rp2350.dtsi:406 */
			reg = < 0x400f8000 0x200 >;             /* in zephyr/dts/vendor/raspberrypi/rpi_pico/rp2350.dtsi:407 */
			status = "disabled";                    /* in zephyr/dts/vendor/raspberrypi/rpi_pico/rp2350.dtsi:408 */
		};

		/* node '/soc/vreg@40100000' defined in zephyr/dts/vendor/raspberrypi/rpi_pico/rp2350.dtsi:411 */
		vreg: vreg@40100000 {
			compatible = "raspberrypi,core-supply-regulator"; /* in zephyr/dts/vendor/raspberrypi/rpi_pico/rp2350.dtsi:412 */
			reg = < 0x40100000 0x200 >;                       /* in zephyr/dts/vendor/raspberrypi/rpi_pico/rp2350.dtsi:413 */
			raspberrypi,brown-out-detection;                  /* in zephyr/dts/vendor/raspberrypi/rpi_pico/rp2350.dtsi:415 */
			status = "okay";                                  /* in zephyr/boards/raspberrypi/rpi_pico2/rpi_pico2_cpu0_common.dtsi:78 */
		};

		/* node '/soc/dma@50000000' defined in zephyr/dts/vendor/raspberrypi/rpi_pico/rp2350.dtsi:418 */
		dma: dma@50000000 {
			compatible = "raspberrypi,pico-dma"; /* in zephyr/dts/vendor/raspberrypi/rpi_pico/rp2350.dtsi:419 */
			reg = < 0x50000000 0x10000 >;        /* in zephyr/dts/vendor/raspberrypi/rpi_pico/rp2350.dtsi:420 */
			resets = < &reset 0x2 >;             /* in zephyr/dts/vendor/raspberrypi/rpi_pico/rp2350.dtsi:421 */
			clocks = < &clocks 0x5 >;            /* in zephyr/dts/vendor/raspberrypi/rpi_pico/rp2350.dtsi:422 */
			interrupts = < 0xa 0x7 >,
			             < 0xb 0x7 >,
			             < 0xc 0x7 >,
			             < 0xd 0x7 >;            /* in zephyr/dts/vendor/raspberrypi/rpi_pico/rp2350.dtsi:423 */
			interrupt-names = "dma0",
			                  "dma1",
			                  "dma2",
			                  "dma3";            /* in zephyr/dts/vendor/raspberrypi/rpi_pico/rp2350.dtsi:427 */
			dma-channels = < 0x10 >;             /* in zephyr/dts/vendor/raspberrypi/rpi_pico/rp2350.dtsi:428 */
			status = "disabled";                 /* in zephyr/dts/vendor/raspberrypi/rpi_pico/rp2350.dtsi:429 */
			#dma-cells = < 0x3 >;                /* in zephyr/dts/vendor/raspberrypi/rpi_pico/rp2350.dtsi:430 */
		};

		/* node '/soc/usbd@50110000' defined in zephyr/dts/vendor/raspberrypi/rpi_pico/rp2350.dtsi:433 */
		usbd: zephyr_udc0: usbd@50110000 {
			compatible = "raspberrypi,pico-usbd"; /* in zephyr/dts/vendor/raspberrypi/rpi_pico/rp2350.dtsi:434 */
			reg = < 0x50110000 0x10000 >;         /* in zephyr/dts/vendor/raspberrypi/rpi_pico/rp2350.dtsi:435 */
			resets = < &reset 0x1c >;             /* in zephyr/dts/vendor/raspberrypi/rpi_pico/rp2350.dtsi:436 */
			clocks = < &clocks 0x8 >;             /* in zephyr/dts/vendor/raspberrypi/rpi_pico/rp2350.dtsi:437 */
			interrupts = < 0xe 0x7 >;             /* in zephyr/dts/vendor/raspberrypi/rpi_pico/rp2350.dtsi:438 */
			interrupt-names = "usbctrl";          /* in zephyr/dts/vendor/raspberrypi/rpi_pico/rp2350.dtsi:439 */
			num-bidir-endpoints = < 0x10 >;       /* in zephyr/dts/vendor/raspberrypi/rpi_pico/rp2350.dtsi:440 */
			status = "okay";                      /* in zephyr/boards/raspberrypi/rpi_pico2/rpi_pico2_cpu0_common.dtsi:86 */
		};

		/* node '/soc/pio@50200000' defined in zephyr/dts/vendor/raspberrypi/rpi_pico/rp2350.dtsi:444 */
		pio0: pio@50200000 {
			compatible = "raspberrypi,pico-pio"; /* in zephyr/dts/vendor/raspberrypi/rpi_pico/rp2350.dtsi:445 */
			reg = < 0x50200000 0x1000 >;         /* in zephyr/dts/vendor/raspberrypi/rpi_pico/rp2350.dtsi:446 */
			clocks = < &clocks 0x5 >;            /* in zephyr/dts/vendor/raspberrypi/rpi_pico/rp2350.dtsi:447 */
			resets = < &reset 0xb >;             /* in zephyr/dts/vendor/raspberrypi/rpi_pico/rp2350.dtsi:448 */
			interrupts = < 0xf 0x7 >,
			             < 0x10 0x7 >;           /* in zephyr/dts/vendor/raspberrypi/rpi_pico/rp2350.dtsi:449 */
			interrupt-names = "irq0",
			                  "irq1";            /* in zephyr/dts/vendor/raspberrypi/rpi_pico/rp2350.dtsi:451 */
			status = "disabled";                 /* in zephyr/dts/vendor/raspberrypi/rpi_pico/rp2350.dtsi:452 */
		};

		/* node '/soc/pio@50300000' defined in zephyr/dts/vendor/raspberrypi/rpi_pico/rp2350.dtsi:455 */
		pio1: pio@50300000 {
			compatible = "raspberrypi,pico-pio"; /* in zephyr/dts/vendor/raspberrypi/rpi_pico/rp2350.dtsi:456 */
			reg = < 0x50300000 0x1000 >;         /* in zephyr/dts/vendor/raspberrypi/rpi_pico/rp2350.dtsi:457 */
			clocks = < &clocks 0x5 >;            /* in zephyr/dts/vendor/raspberrypi/rpi_pico/rp2350.dtsi:458 */
			resets = < &reset 0xc >;             /* in zephyr/dts/vendor/raspberrypi/rpi_pico/rp2350.dtsi:459 */
			interrupts = < 0x11 0x7 >,
			             < 0x12 0x7 >;           /* in zephyr/dts/vendor/raspberrypi/rpi_pico/rp2350.dtsi:460 */
			interrupt-names = "irq0",
			                  "irq1";            /* in zephyr/dts/vendor/raspberrypi/rpi_pico/rp2350.dtsi:462 */
			status = "disabled";                 /* in zephyr/dts/vendor/raspberrypi/rpi_pico/rp2350.dtsi:463 */
		};

		/* node '/soc/pio@50400000' defined in zephyr/dts/vendor/raspberrypi/rpi_pico/rp2350.dtsi:466 */
		pio2: pio@50400000 {
			compatible = "raspberrypi,pico-pio"; /* in zephyr/dts/vendor/raspberrypi/rpi_pico/rp2350.dtsi:467 */
			reg = < 0x50400000 0x1000 >;         /* in zephyr/dts/vendor/raspberrypi/rpi_pico/rp2350.dtsi:468 */
			clocks = < &clocks 0x5 >;            /* in zephyr/dts/vendor/raspberrypi/rpi_pico/rp2350.dtsi:469 */
			resets = < &reset 0xd >;             /* in zephyr/dts/vendor/raspberrypi/rpi_pico/rp2350.dtsi:470 */
			interrupts = < 0x13 0x7 >,
			             < 0x14 0x7 >;           /* in zephyr/dts/vendor/raspberrypi/rpi_pico/rp2350.dtsi:471 */
			interrupt-names = "irq0",
			                  "irq1";            /* in zephyr/dts/vendor/raspberrypi/rpi_pico/rp2350.dtsi:473 */
			status = "disabled";                 /* in zephyr/dts/vendor/raspberrypi/rpi_pico/rp2350.dtsi:474 */
		};

		/* node '/soc/rng@400f0000' defined in zephyr/dts/vendor/raspberrypi/rpi_pico/rp2350.dtsi:477 */
		rng: rng@400f0000 {
			compatible = "raspberrypi,pico-rng"; /* in zephyr/dts/vendor/raspberrypi/rpi_pico/rp2350.dtsi:478 */
			reg = < 0x400f0000 0x1000 >;         /* in zephyr/dts/vendor/raspberrypi/rpi_pico/rp2350.dtsi:479 */
			status = "okay";                     /* in zephyr/boards/raspberrypi/rpi_pico2/rpi_pico2_cpu0_common.dtsi:82 */
		};

		/* node '/soc/sio@d0000000' defined in zephyr/dts/vendor/raspberrypi/rpi_pico/rp2350.dtsi:483 */
		sio: sio@d0000000 {
			compatible = "raspberrypi,pico-sio"; /* in zephyr/dts/vendor/raspberrypi/rpi_pico/rp2350.dtsi:484 */
			reg = < 0xd0000000 0x14000 >;        /* in zephyr/dts/vendor/raspberrypi/rpi_pico/rp2350.dtsi:485 */

			/* node '/soc/sio@d0000000/mbox' defined in zephyr/dts/vendor/raspberrypi/rpi_pico/rp2350.dtsi:487 */
			mbox: mbox {
				compatible = "raspberrypi,pico-mbox"; /* in zephyr/dts/vendor/raspberrypi/rpi_pico/rp2350.dtsi:488 */
				interrupts = < 0x19 0x7 >;            /* in zephyr/dts/vendor/raspberrypi/rpi_pico/rp2350.dtsi:489 */
				interrupt-names = "mbox";             /* in zephyr/dts/vendor/raspberrypi/rpi_pico/rp2350.dtsi:490 */
				fifo-depth = < 0x4 >;                 /* in zephyr/dts/vendor/raspberrypi/rpi_pico/rp2350.dtsi:491 */
				#mbox-cells = < 0x0 >;                /* in zephyr/dts/vendor/raspberrypi/rpi_pico/rp2350.dtsi:492 */
				status = "disabled";                  /* in zephyr/dts/vendor/raspberrypi/rpi_pico/rp2350.dtsi:493 */
				phandle = < 0x1d >;                   /* in zephyr/dts/vendor/raspberrypi/rpi_pico/rp2350.dtsi:506 */
			};
		};

		/* node '/soc/interrupt-controller@e000e100' defined in zephyr/dts/arm/armv8-m.dtsi:13 */
		nvic: interrupt-controller@e000e100 {
			#address-cells = < 0x1 >;            /* in zephyr/dts/arm/armv8-m.dtsi:14 */
			compatible = "arm,v8m-nvic";         /* in zephyr/dts/arm/armv8-m.dtsi:15 */
			reg = < 0xe000e100 0xc00 >;          /* in zephyr/dts/arm/armv8-m.dtsi:16 */
			interrupt-controller;                /* in zephyr/dts/arm/armv8-m.dtsi:17 */
			#interrupt-cells = < 0x2 >;          /* in zephyr/dts/arm/armv8-m.dtsi:18 */
			arm,num-irq-priority-bits = < 0x4 >; /* in zephyr/dts/arm/raspberrypi/rpi_pico/m33.dtsi:21 */
			phandle = < 0x6 >;                   /* in zephyr/dts/arm/armv8-m.dtsi:10 */
		};

		/* node '/soc/timer@e000e010' defined in zephyr/dts/arm/armv8-m.dtsi:21 */
		systick: timer@e000e010 {
			compatible = "arm,armv8m-systick"; /* in zephyr/dts/arm/armv8-m.dtsi:22 */
			reg = < 0xe000e010 0x10 >;         /* in zephyr/dts/arm/armv8-m.dtsi:23 */
		};
	};

	/* node '/ipm-mbox' defined in zephyr/dts/vendor/raspberrypi/rpi_pico/rp2350.dtsi:498 */
	ipm_mbox: ipm-mbox {
		compatible = "zephyr,mbox-ipm"; /* in zephyr/dts/vendor/raspberrypi/rpi_pico/rp2350.dtsi:505 */
		mboxes = < &mbox >,
		         < &mbox >;             /* in zephyr/dts/vendor/raspberrypi/rpi_pico/rp2350.dtsi:506 */
		mbox-names = "tx",
		             "rx";              /* in zephyr/dts/vendor/raspberrypi/rpi_pico/rp2350.dtsi:507 */
		status = "disabled";            /* in zephyr/dts/vendor/raspberrypi/rpi_pico/rp2350.dtsi:508 */
	};

	/* node '/pin-controller' defined in zephyr/dts/vendor/raspberrypi/rpi_pico/rp2350.dtsi:511 */
	pinctrl: pin-controller {
		compatible = "raspberrypi,pico-pinctrl"; /* in zephyr/dts/vendor/raspberrypi/rpi_pico/rp2350.dtsi:512 */
		status = "okay";                         /* in zephyr/dts/vendor/raspberrypi/rpi_pico/rp2350.dtsi:513 */

		/* node '/pin-controller/uart0_default' defined in zephyr/boards/raspberrypi/common/rpi_pico-pinctrl-common.dtsi:8 */
		uart0_default: uart0_default {
			phandle = < 0x17 >; /* in zephyr/boards/raspberrypi/rpi_pico2/rpi_pico2_cpu0_common.dtsi:33 */

			/* node '/pin-controller/uart0_default/group1' defined in zephyr/boards/raspberrypi/common/rpi_pico-pinctrl-common.dtsi:9 */
			group1 {
				pinmux = < 0x2 >; /* in zephyr/boards/raspberrypi/common/rpi_pico-pinctrl-common.dtsi:10 */
			};

			/* node '/pin-controller/uart0_default/group2' defined in zephyr/boards/raspberrypi/common/rpi_pico-pinctrl-common.dtsi:13 */
			group2 {
				pinmux = < 0x22 >; /* in zephyr/boards/raspberrypi/common/rpi_pico-pinctrl-common.dtsi:14 */
				input-enable;      /* in zephyr/boards/raspberrypi/common/rpi_pico-pinctrl-common.dtsi:15 */
			};
		};

		/* node '/pin-controller/i2c0_default' defined in zephyr/boards/raspberrypi/common/rpi_pico-pinctrl-common.dtsi:19 */
		i2c0_default: i2c0_default {
			phandle = < 0x19 >; /* in zephyr/boards/raspberrypi/rpi_pico2/rpi_pico2_cpu0_common.dtsi:45 */

			/* node '/pin-controller/i2c0_default/group1' defined in zephyr/boards/raspberrypi/common/rpi_pico-pinctrl-common.dtsi:20 */
			group1 {
				pinmux = < 0x83 >,
				         < 0xa3 >;    /* in zephyr/boards/raspberrypi/common/rpi_pico-pinctrl-common.dtsi:21 */
				input-enable;         /* in zephyr/boards/raspberrypi/common/rpi_pico-pinctrl-common.dtsi:22 */
				input-schmitt-enable; /* in zephyr/boards/raspberrypi/common/rpi_pico-pinctrl-common.dtsi:23 */
			};
		};

		/* node '/pin-controller/i2c1_default' defined in zephyr/boards/raspberrypi/common/rpi_pico-pinctrl-common.dtsi:27 */
		i2c1_default: i2c1_default {
			phandle = < 0x1a >; /* in zephyr/boards/raspberrypi/rpi_pico2/rpi_pico2_cpu0_common.dtsi:52 */

			/* node '/pin-controller/i2c1_default/group1' defined in zephyr/boards/raspberrypi/common/rpi_pico-pinctrl-common.dtsi:28 */
			group1 {
				pinmux = < 0xc3 >,
				         < 0xe3 >;    /* in zephyr/boards/raspberrypi/common/rpi_pico-pinctrl-common.dtsi:29 */
				input-enable;         /* in zephyr/boards/raspberrypi/common/rpi_pico-pinctrl-common.dtsi:30 */
				input-schmitt-enable; /* in zephyr/boards/raspberrypi/common/rpi_pico-pinctrl-common.dtsi:31 */
			};
		};

		/* node '/pin-controller/spi0_default' defined in zephyr/boards/raspberrypi/common/rpi_pico-pinctrl-common.dtsi:35 */
		spi0_default: spi0_default {
			phandle = < 0x18 >; /* in zephyr/boards/raspberrypi/rpi_pico2/rpi_pico2_cpu0_common.dtsi:39 */

			/* node '/pin-controller/spi0_default/group1' defined in zephyr/boards/raspberrypi/common/rpi_pico-pinctrl-common.dtsi:36 */
			group1 {
				pinmux = < 0x221 >,
				         < 0x241 >,
				         < 0x261 >; /* in zephyr/boards/raspberrypi/common/rpi_pico-pinctrl-common.dtsi:37 */
			};

			/* node '/pin-controller/spi0_default/group2' defined in zephyr/boards/raspberrypi/common/rpi_pico-pinctrl-common.dtsi:40 */
			group2 {
				pinmux = < 0x201 >; /* in zephyr/boards/raspberrypi/common/rpi_pico-pinctrl-common.dtsi:41 */
				input-enable;       /* in zephyr/boards/raspberrypi/common/rpi_pico-pinctrl-common.dtsi:42 */
			};
		};

		/* node '/pin-controller/pwm_ch4b_default' defined in zephyr/boards/raspberrypi/common/rpi_pico-pinctrl-common.dtsi:46 */
		pwm_ch4b_default: pwm_ch4b_default {
			phandle = < 0x1c >; /* in zephyr/boards/raspberrypi/rpi_pico2/rpi_pico2_cpu0_common.dtsi:64 */

			/* node '/pin-controller/pwm_ch4b_default/group1' defined in zephyr/boards/raspberrypi/common/rpi_pico-pinctrl-common.dtsi:47 */
			group1 {
				pinmux = < 0x324 >; /* in zephyr/boards/raspberrypi/common/rpi_pico-pinctrl-common.dtsi:48 */
			};
		};

		/* node '/pin-controller/adc_default' defined in zephyr/boards/raspberrypi/common/rpi_pico-pinctrl-common.dtsi:52 */
		adc_default: adc_default {
			phandle = < 0x1b >; /* in zephyr/boards/raspberrypi/rpi_pico2/rpi_pico2_cpu0_common.dtsi:58 */

			/* node '/pin-controller/adc_default/group1' defined in zephyr/boards/raspberrypi/common/rpi_pico-pinctrl-common.dtsi:53 */
			group1 {
				pinmux = < 0x35f >,
				         < 0x37f >,
				         < 0x39f >,
				         < 0x3bf >; /* in zephyr/boards/raspberrypi/common/rpi_pico-pinctrl-common.dtsi:54 */
				input-enable;       /* in zephyr/boards/raspberrypi/common/rpi_pico-pinctrl-common.dtsi:55 */
			};
		};
	};

	/* node '/dietemp' defined in zephyr/dts/vendor/raspberrypi/rpi_pico/rp2350.dtsi:516 */
	die_temp: dietemp {
		compatible = "raspberrypi,pico-temp"; /* in zephyr/dts/vendor/raspberrypi/rpi_pico/rp2350.dtsi:517 */
		status = "okay";                      /* in zephyr/dts/vendor/raspberrypi/rpi_pico/rp2350.dtsi:518 */
		io-channels = < &adc 0x4 >;           /* in zephyr/dts/vendor/raspberrypi/rpi_pico/rp2350a.dtsi:8 */
	};

	/* node '/connector' defined in zephyr/boards/raspberrypi/rpi_pico2/rpi_pico2_common.dtsi:12 */
	pico_header: connector {
		compatible = "raspberrypi,pico-header";    /* in zephyr/boards/raspberrypi/rpi_pico2/rpi_pico2_common.dtsi:13 */
		#gpio-cells = < 0x2 >;                     /* in zephyr/boards/raspberrypi/rpi_pico2/rpi_pico2_common.dtsi:14 */
		gpio-map-mask = < 0xffffffff 0xffffffc0 >; /* in zephyr/boards/raspberrypi/rpi_pico2/rpi_pico2_common.dtsi:15 */
		gpio-map-pass-thru = < 0x0 0x3f >;         /* in zephyr/boards/raspberrypi/rpi_pico2/rpi_pico2_common.dtsi:16 */
		gpio-map = < 0x0 0x0 &gpio0 0x0 0x0 >,
		           < 0x1 0x0 &gpio0 0x1 0x0 >,
		           < 0x2 0x0 &gpio0 0x2 0x0 >,
		           < 0x3 0x0 &gpio0 0x3 0x0 >,
		           < 0x4 0x0 &gpio0 0x4 0x0 >,
		           < 0x5 0x0 &gpio0 0x5 0x0 >,
		           < 0x6 0x0 &gpio0 0x6 0x0 >,
		           < 0x7 0x0 &gpio0 0x7 0x0 >,
		           < 0x8 0x0 &gpio0 0x8 0x0 >,
		           < 0x9 0x0 &gpio0 0x9 0x0 >,
		           < 0xa 0x0 &gpio0 0xa 0x0 >,
		           < 0xb 0x0 &gpio0 0xb 0x0 >,
		           < 0xc 0x0 &gpio0 0xc 0x0 >,
		           < 0xd 0x0 &gpio0 0xd 0x0 >,
		           < 0xe 0x0 &gpio0 0xe 0x0 >,
		           < 0xf 0x0 &gpio0 0xf 0x0 >,
		           < 0x10 0x0 &gpio0 0x10 0x0 >,
		           < 0x11 0x0 &gpio0 0x11 0x0 >,
		           < 0x12 0x0 &gpio0 0x12 0x0 >,
		           < 0x13 0x0 &gpio0 0x13 0x0 >,
		           < 0x14 0x0 &gpio0 0x14 0x0 >,
		           < 0x15 0x0 &gpio0 0x15 0x0 >,
		           < 0x16 0x0 &gpio0 0x16 0x0 >,
		           < 0x1a 0x0 &gpio0 0x1a 0x0 >,
		           < 0x1b 0x0 &gpio0 0x1b 0x0 >,
		           < 0x1c 0x0 &gpio0 0x1c 0x0 >;   /* in zephyr/boards/raspberrypi/rpi_pico2/rpi_pico2_common.dtsi:17 */
	};

	/* node '/leds' defined in zephyr/boards/raspberrypi/common/rpi_pico-led.dtsi:9 */
	leds {
		compatible = "gpio-leds"; /* in zephyr/boards/raspberrypi/common/rpi_pico-led.dtsi:10 */

		/* node '/leds/led_0' defined in zephyr/boards/raspberrypi/common/rpi_pico-led.dtsi:12 */
		led0: led_0 {
			gpios = < &gpio0 0x19 0x0 >; /* in zephyr/boards/raspberrypi/common/rpi_pico-led.dtsi:13 */
			label = "LED";               /* in zephyr/boards/raspberrypi/common/rpi_pico-led.dtsi:14 */
		};
	};

	/* node '/pwm_leds' defined in zephyr/boards/raspberrypi/common/rpi_pico-led.dtsi:18 */
	pwm_leds {
		compatible = "pwm-leds"; /* in zephyr/boards/raspberrypi/common/rpi_pico-led.dtsi:19 */
		status = "disabled";     /* in zephyr/boards/raspberrypi/common/rpi_pico-led.dtsi:20 */

		/* node '/pwm_leds/pwm_led_0' defined in zephyr/boards/raspberrypi/common/rpi_pico-led.dtsi:22 */
		pwm_led0: pwm_led_0 {
			pwms = < &pwm 0x9 0x1312d00 0x0 >; /* in zephyr/boards/raspberrypi/common/rpi_pico-led.dtsi:23 */
			label = "PWM_LED";                 /* in zephyr/boards/raspberrypi/common/rpi_pico-led.dtsi:24 */
		};
	};
};
